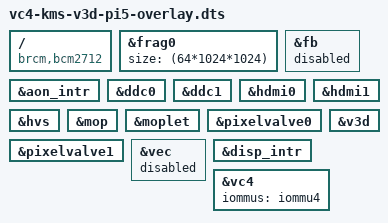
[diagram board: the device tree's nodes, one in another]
// SPDX-License-Identifier: GPL-2.0

#include "cma-overlay.dts"

&frag0 {
	size = <(64*1024*1024)>;
};

/ {
	compatible = "brcm,bcm2712";

	fragment@1 {
		target = <&fb>;
		__overlay__ {
			status = "disabled";
		};
	};

	fragment@2 {
		target = <&aon_intr>;
		__overlay__ {
			status = "okay";
		};
	};

	fragment@3 {
		target = <&ddc0>;
		__overlay__ {
			status = "okay";
		};
	};

	fragment@4 {
		target = <&ddc1>;
		__overlay__ {
			status = "okay";
		};
	};

	fragment@5 {
		target = <&hdmi0>;
		__overlay__ {
			status = "okay";
		};
	};

	fragment@6 {
		target = <&hdmi1>;
		__overlay__ {
			status = "okay";
		};
	};

	fragment@7 {
		target = <&hvs>;
		__overlay__ {
			status = "okay";
		};
	};

	fragment@8 {
		target = <&mop>;
		__overlay__ {
			status = "okay";
		};
	};

	fragment@9 {
		target = <&moplet>;
		__overlay__ {
			status = "okay";
		};
	};

	fragment@10 {
		target = <&pixelvalve0>;
		__overlay__ {
			status = "okay";
		};
	};

	fragment@11 {
		target = <&pixelvalve1>;
		__overlay__ {
			status = "okay";
		};
	};

	fragment@12 {
		target = <&v3d>;
		__overlay__ {
			status = "okay";
		};
	};

	fragment@13 {
		target = <&vec>;
		frag13: __overlay__ {
			status = "disabled";
		};
	};

	fragment@14 {
		target = <&hdmi0>;
		__dormant__  {
			dmas;
		};
	};

	fragment@15 {
		target = <&hdmi1>;
		__dormant__  {
			dmas;
		};
	};

	fragment@16 {
		target = <&disp_intr>;
		__overlay__  {
			status = "okay";
		};
	};

	fragment@17 {
		target = <&vc4>;
		__overlay__  {
			/* IOMMU attaches here, where we allocate DMA buffers */
			iommus = <&iommu4>;
		};
	};

	__overrides__ {
		audio   = <0>,"!14";
		audio1   = <0>,"!15";
		noaudio = <0>,"=14", <0>,"=15";
		composite = <0>, "!3",
			    <0>, "!4",
			    <0>, "!5",
			    <0>, "!6",
			    <0>, "!10",
			    <0>, "!11",
			    <&frag13>, "status";
		nohdmi0 =   <0>, "-3-5-10";
		nohdmi1 =   <0>, "-4-6-11";
		nohdmi =    <0>, "-3-4-5-6-10-11";
	};
};
